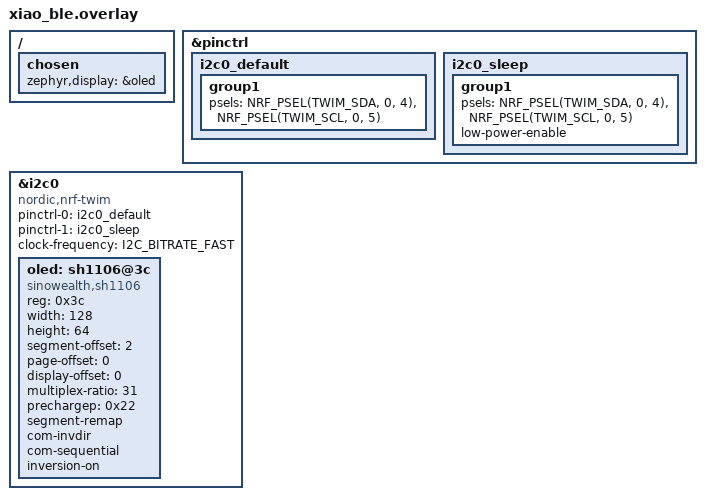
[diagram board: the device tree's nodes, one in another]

/**
 * Generated by Shield Wizard for ZMK
 * Applies to shield "hamdactyl_dongle" with board "seeeduino_xiao_ble" only
 */

//
// ======== i2c0 ========
//

// pin control for i2c0
// - SDA on D4
// - SCL on D5
&pinctrl {
    /* configuration for i2c0 device, default state */
    i2c0_default: i2c0_default {
        group1 {
            psels = <NRF_PSEL(TWIM_SDA, 0, 4)>,
                    <NRF_PSEL(TWIM_SCL, 0, 5)>;
        };
    };
    /* configuration for i2c0 device, sleep state */
    i2c0_sleep: i2c0_sleep {
        group1 {
            psels = <NRF_PSEL(TWIM_SDA, 0, 4)>,
                    <NRF_PSEL(TWIM_SCL, 0, 5)>;
            low-power-enable;
        };
    };
};
&i2c0 {
  compatible = "nordic,nrf-twim";
  status = "okay";
  pinctrl-0 = <&i2c0_default>;
  pinctrl-1 = <&i2c0_sleep>;
  pinctrl-names = "default", "sleep";
  clock-frequency = <I2C_BITRATE_FAST>;
};

// devices on i2c0

&i2c0 {
    oled: sh1106@3c {
        compatible = "sinowealth,sh1106";
        reg = <0x3c>;
        width = <128>;
        height = <64>;

        segment-offset = <2>;
        page-offset = <0>;
        display-offset = <0>;
        multiplex-ratio = <31>;
        prechargep = <0x22>;
        segment-remap;
        com-invdir;
        com-sequential;
        inversion-on;
    };
};
/ {
    chosen {
        zephyr,display = &oled;
    };
};
